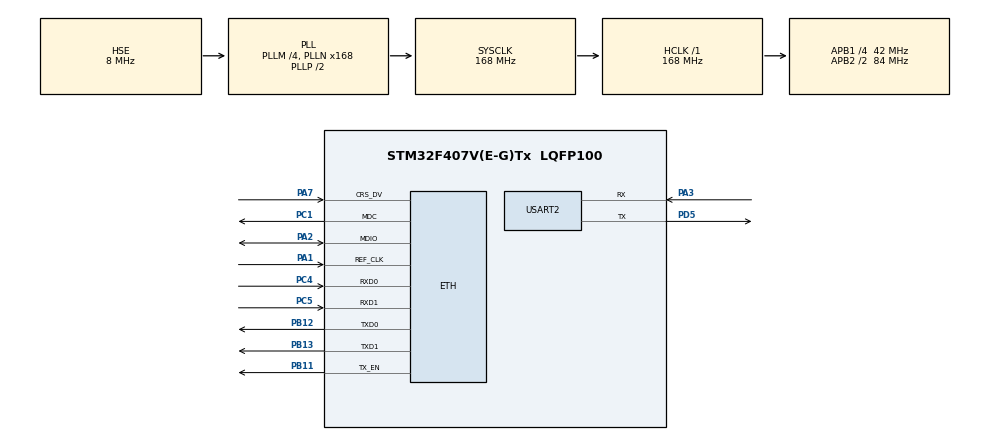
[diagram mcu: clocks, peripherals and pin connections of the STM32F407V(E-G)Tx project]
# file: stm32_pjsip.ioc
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ETH.MediaInterface=HAL_ETH_RMII_MODE
ETH.PHY_Name_RMII=DP83848_PHY_ADDRESS
LWIP.BSP.number=1
LWIP.LWIP_DHCP=0
LWIP.Version=v2.1.2_Cube
LWIP0.BSP.STBoard=false
LWIP0.BSP.api=BSP_COMPONENT_DRIVER
LWIP0.BSP.component=DP83848
LWIP0.BSP.instance=DP83848
LWIP0.BSP.name=Driver_PHY
LWIP0.BSP.semaphore=S_DP83848
LWIP0.BSP.solution=DP83848
Mcu.Family=STM32F4
Mcu.Name=STM32F407V(E-G)Tx
Mcu.Package=LQFP100
NVIC.PriorityGroup=NVIC_PRIORITYGROUP_4
PA1.Mode=RMII
PA1.Signal=ETH_REF_CLK
PA13.Mode=Serial_Wire
PA13.Signal=SYS_JTMS-SWDIO
PA14.Mode=Serial_Wire
PA14.Signal=SYS_JTCK-SWCLK
PA2.Mode=RMII
PA2.Signal=ETH_MDIO
PA3.Mode=Asynchronous
PA3.Signal=USART2_RX
PA7.Mode=RMII
PA7.Signal=ETH_CRS_DV
PB11.Mode=RMII
PB11.Signal=ETH_TX_EN
PB12.Mode=RMII
PB12.Signal=ETH_TXD0
PB13.Mode=RMII
PB13.Signal=ETH_TXD1
PC1.Mode=RMII
PC1.Signal=ETH_MDC
PC14-OSC32_IN.Mode=LSE-External-Oscillator
PC14-OSC32_IN.Signal=RCC_OSC32_IN
PC15-OSC32_OUT.Mode=LSE-External-Oscillator
PC15-OSC32_OUT.Signal=RCC_OSC32_OUT
PC4.Mode=RMII
PC4.Signal=ETH_RXD0
PC5.Mode=RMII
PC5.Signal=ETH_RXD1
PD5.Mode=Asynchronous
PD5.Signal=USART2_TX
PH0-OSC_IN.Mode=HSE-External-Oscillator
PH0-OSC_IN.Signal=RCC_OSC_IN
PH1-OSC_OUT.Mode=HSE-External-Oscillator
PH1-OSC_OUT.Signal=RCC_OSC_OUT
ProjectManager.HeapSize=0x200
ProjectManager.StackSize=0x400
ProjectManager.TargetToolchain=STM32CubeIDE
RCC.48MHZClocksFreq_Value=84000000
RCC.AHBFreq_Value=168000000
RCC.APB1CLKDivider=RCC_HCLK_DIV4
RCC.APB1Freq_Value=42000000
RCC.APB1TimFreq_Value=84000000
RCC.APB2CLKDivider=RCC_HCLK_DIV2
RCC.APB2Freq_Value=84000000
RCC.APB2TimFreq_Value=168000000
RCC.CortexFreq_Value=168000000
RCC.HCLKFreq_Value=168000000
RCC.HSE_VALUE=8000000
RCC.HSI_VALUE=16000000
RCC.PLLM=4
RCC.PLLN=168
RCC.PLLSourceVirtual=RCC_PLLSOURCE_HSE
RCC.SYSCLKFreq_VALUE=168000000
RCC.SYSCLKSource=RCC_SYSCLKSOURCE_PLLCLK
RCC.VCOOutputFreq_Value=336000000
USART2.VirtualMode=VM_ASYNC
VP_LWIP_VS_Enabled.Mode=Enabled
board=custom

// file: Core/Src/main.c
/* USER CODE BEGIN Header */
/**
  ******************************************************************************
  * @file           : main.c
  * @brief          : Main program body
  ******************************************************************************
  * @attention
  *
  * Copyright (c) 2023 STMicroelectronics.
  * All rights reserved.
  *
  * This software is licensed under terms that can be found in the LICENSE file
  * in the root directory of this software component.
  * If no LICENSE file comes with this software, it is provided AS-IS.
  *
  ******************************************************************************
  */
/* USER CODE END Header */
#include "main.h"
#include "lwip.h"

/* USER CODE BEGIN Includes */

#include <pjlib.h>
#include <pjlib-util.h>
#include <stdio.h>
#include "test.h"
/* USER CODE END Includes */

/* USER CODE BEGIN PTD */
//pj_pool_factory *mem;
/* USER CODE END PTD */

UART_HandleTypeDef huart2;

void SystemClock_Config(void);
static void MX_GPIO_Init(void);
static void MX_USART2_UART_Init(void);

/* USER CODE BEGIN 0 */
#ifdef __GNUC__
#define PUTCHAR_PROTOTYPE int __io_putchar(int ch)
#else
#define PUTCHAR_PROTOTYPE int fputc(int ch, FILE *f)
#endif

	PUTCHAR_PROTOTYPE
	{
	  HAL_UART_Transmit(&huart2, (uint8_t *)&ch, 1, HAL_MAX_DELAY);
	  return ch;
	}
////////////////////////////////

/*
 * rand_test(), simply generates COUNT number of random number and
 * check that there's no duplicate numbers.
 */

/* USER CODE END 0 */

int main(void)
{

  /* MCU Configuration--------------------------------------------------------*/

  /* Reset of all peripherals, Initializes the Flash interface and the Systick. */
  HAL_Init();

  /* Configure the system clock */
  SystemClock_Config();

  /* Initialize all configured peripherals */
  MX_GPIO_Init();
  MX_LWIP_Init();
  MX_USART2_UART_Init();
  /* USER CODE BEGIN 2 */
//  pj_caching_pool caching_pool;
//  int rc = 0;
//  mem = &caching_pool.factory;
//  pj_log_init();
//  rc = pj_init();
//     if (rc != 0) {
//    	 return rc;
//     }
//
//   pj_caching_pool_init( &caching_pool, NULL, 0 );
  int rc = test_main();
  printf("rc = %d",rc);
  /* USER CODE END 2 */

  /* Infinite loop */
  while (1)
  {

  }
}

void SystemClock_Config(void)
{
  RCC_OscInitTypeDef RCC_OscInitStruct = {0};
  RCC_ClkInitTypeDef RCC_ClkInitStruct = {0};

  /** Configure the main internal regulator output voltage
  */
  __HAL_RCC_PWR_CLK_ENABLE();
  __HAL_PWR_VOLTAGESCALING_CONFIG(PWR_REGULATOR_VOLTAGE_SCALE1);

  /** Initializes the RCC Oscillators according to the specified parameters
  * in the RCC_OscInitTypeDef structure.
  */
  RCC_OscInitStruct.OscillatorType = RCC_OSCILLATORTYPE_HSE;
  RCC_OscInitStruct.HSEState = RCC_HSE_ON;
  RCC_OscInitStruct.PLL.PLLState = RCC_PLL_ON;
  RCC_OscInitStruct.PLL.PLLSource = RCC_PLLSOURCE_HSE;
  RCC_OscInitStruct.PLL.PLLM = 4;
  RCC_OscInitStruct.PLL.PLLN = 168;
  RCC_OscInitStruct.PLL.PLLP = RCC_PLLP_DIV2;
  RCC_OscInitStruct.PLL.PLLQ = 4;
  if (HAL_RCC_OscConfig(&RCC_OscInitStruct) != HAL_OK)
  {
    Error_Handler();
  }

  /** Initializes the CPU, AHB and APB buses clocks
  */
  RCC_ClkInitStruct.ClockType = RCC_CLOCKTYPE_HCLK|RCC_CLOCKTYPE_SYSCLK
                              |RCC_CLOCKTYPE_PCLK1|RCC_CLOCKTYPE_PCLK2;
  RCC_ClkInitStruct.SYSCLKSource = RCC_SYSCLKSOURCE_PLLCLK;
  RCC_ClkInitStruct.AHBCLKDivider = RCC_SYSCLK_DIV1;
  RCC_ClkInitStruct.APB1CLKDivider = RCC_HCLK_DIV4;
  RCC_ClkInitStruct.APB2CLKDivider = RCC_HCLK_DIV2;

  if (HAL_RCC_ClockConfig(&RCC_ClkInitStruct, FLASH_LATENCY_5) != HAL_OK)
  {
    Error_Handler();
  }
}

static void MX_USART2_UART_Init(void)
{

  huart2.Instance = USART2;
  huart2.Init.BaudRate = 115200;
  huart2.Init.WordLength = UART_WORDLENGTH_8B;
  huart2.Init.StopBits = UART_STOPBITS_1;
  huart2.Init.Parity = UART_PARITY_NONE;
  huart2.Init.Mode = UART_MODE_TX_RX;
  huart2.Init.HwFlowCtl = UART_HWCONTROL_NONE;
  huart2.Init.OverSampling = UART_OVERSAMPLING_16;
  if (HAL_UART_Init(&huart2) != HAL_OK)
  {
    Error_Handler();
  }

}

static void MX_GPIO_Init(void)
{

  /* GPIO Ports Clock Enable */
  __HAL_RCC_GPIOC_CLK_ENABLE();
  __HAL_RCC_GPIOH_CLK_ENABLE();
  __HAL_RCC_GPIOA_CLK_ENABLE();
  __HAL_RCC_GPIOB_CLK_ENABLE();
  __HAL_RCC_GPIOD_CLK_ENABLE();

}

void Error_Handler(void)
{
  __disable_irq();
  while (1)
  {
  }
}
